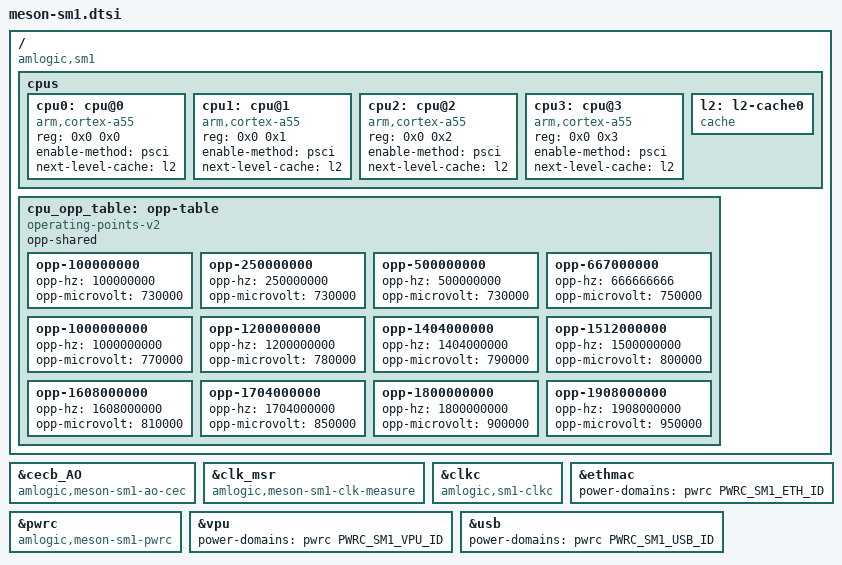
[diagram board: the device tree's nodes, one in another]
// SPDX-License-Identifier: (GPL-2.0+ OR MIT)
/*
 * Copyright (c) 2019 BayLibre, SAS
 * Author: Neil Armstrong <narmstrong@baylibre.com>
 */

#include "meson-g12-common.dtsi"
#include <dt-bindings/power/meson-sm1-power.h>

/ {
	compatible = "amlogic,sm1";

	cpus {
		#address-cells = <0x2>;
		#size-cells = <0x0>;

		cpu0: cpu@0 {
			device_type = "cpu";
			compatible = "arm,cortex-a55";
			reg = <0x0 0x0>;
			enable-method = "psci";
			next-level-cache = <&l2>;
		};

		cpu1: cpu@1 {
			device_type = "cpu";
			compatible = "arm,cortex-a55";
			reg = <0x0 0x1>;
			enable-method = "psci";
			next-level-cache = <&l2>;
		};

		cpu2: cpu@2 {
			device_type = "cpu";
			compatible = "arm,cortex-a55";
			reg = <0x0 0x2>;
			enable-method = "psci";
			next-level-cache = <&l2>;
		};

		cpu3: cpu@3 {
			device_type = "cpu";
			compatible = "arm,cortex-a55";
			reg = <0x0 0x3>;
			enable-method = "psci";
			next-level-cache = <&l2>;
		};

		l2: l2-cache0 {
			compatible = "cache";
		};
	};

	cpu_opp_table: opp-table {
		compatible = "operating-points-v2";
		opp-shared;

		opp-100000000 {
			opp-hz = /bits/ 64 <100000000>;
			opp-microvolt = <730000>;
		};

		opp-250000000 {
			opp-hz = /bits/ 64 <250000000>;
			opp-microvolt = <730000>;
		};

		opp-500000000 {
			opp-hz = /bits/ 64 <500000000>;
			opp-microvolt = <730000>;
		};

		opp-667000000 {
			opp-hz = /bits/ 64 <666666666>;
			opp-microvolt = <750000>;
		};

		opp-1000000000 {
			opp-hz = /bits/ 64 <1000000000>;
			opp-microvolt = <770000>;
		};

		opp-1200000000 {
			opp-hz = /bits/ 64 <1200000000>;
			opp-microvolt = <780000>;
		};

		opp-1404000000 {
			opp-hz = /bits/ 64 <1404000000>;
			opp-microvolt = <790000>;
		};

		opp-1512000000 {
			opp-hz = /bits/ 64 <1500000000>;
			opp-microvolt = <800000>;
		};

		opp-1608000000 {
			opp-hz = /bits/ 64 <1608000000>;
			opp-microvolt = <810000>;
		};

		opp-1704000000 {
			opp-hz = /bits/ 64 <1704000000>;
			opp-microvolt = <850000>;
		};

		opp-1800000000 {
			opp-hz = /bits/ 64 <1800000000>;
			opp-microvolt = <900000>;
		};

		opp-1908000000 {
			opp-hz = /bits/ 64 <1908000000>;
			opp-microvolt = <950000>;
		};
	};
};

&cecb_AO {
	compatible = "amlogic,meson-sm1-ao-cec";
};

&clk_msr {
	compatible = "amlogic,meson-sm1-clk-measure";
};


&clkc {
	compatible = "amlogic,sm1-clkc";
};

&ethmac {
	power-domains = <&pwrc PWRC_SM1_ETH_ID>;
};

&pwrc {
	compatible = "amlogic,meson-sm1-pwrc";
};

&vpu {
	power-domains = <&pwrc PWRC_SM1_VPU_ID>;
};

&usb {
	power-domains = <&pwrc PWRC_SM1_USB_ID>;
};
